# ATmega16A device description
Architecture: AVR8; Family: megaAVR
Registers are 8-bit, access not given, no defined reset value unless marked. A register's access mark holds for its fields unless they carry their own. Offsets are from the block's base; [hi:lo] are bit positions; 'fields as' and 'values as' point back to an identical list.

## EXINT — External Interrupts
Instances: EXINT 0x00
0x54 MCUCSR — MCU Control And Status Register
  [6] ISC2 — Interrupt Sense Control 2
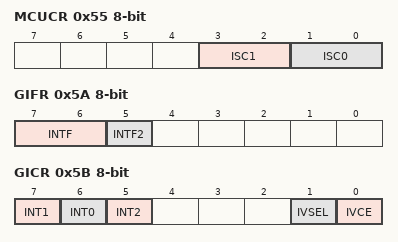
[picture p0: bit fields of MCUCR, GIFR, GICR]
0x55 MCUCR — General Interrupt Control Register
  [3:2] ISC1 — Interrupt Sense Control 1 Bits
    0=Low Level of INTX; 1=Any Logical Change of INTX; 2=Falling Edge of INTX; 3=Rising Edge of INTX
  [1:0] ISC0 — Interrupt Sense Control 0 Bits
    values as ISC1
0x5A GIFR — General Interrupt Flag Register
  [7:6] INTF — External Interrupt Flags
  [5] INTF2 — External Interrupt Flag 2
0x5B GICR — General Interrupt Control Register
  [7] INT1 — External Interrupt Request 1 Enable
  [6] INT0 — External Interrupt Request 0 Enable
  [5] INT2 — External Interrupt Request 2 Enable
  [1] IVSEL — Interrupt Vector Select
  [0] IVCE — Interrupt Vector Change Enable

## EEPROM
Instances: EEPROM 0x00
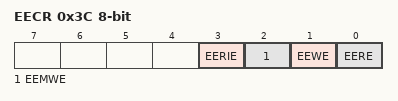
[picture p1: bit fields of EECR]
0x3C EECR — EEPROM Control Register
  [3] EERIE — EEPROM Ready Interrupt Enable
  [2] EEMWE — EEPROM Master Write Enable
  [1] EEWE — EEPROM Write Enable
  [0] EERE — EEPROM Read Enable
0x3D EEDR — EEPROM Data Register
  [7:0] EEDR — EEPROM Data bits
0x3E EEAR 16-bit — EEPROM Address Register Bytes
  [8:0] EEAR — EEPROM Address bits

## CPU — CPU Registers
Instances: CPU 0x00
Parameters: CORE_VERSION=V2E
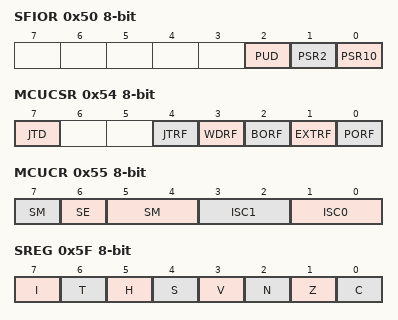
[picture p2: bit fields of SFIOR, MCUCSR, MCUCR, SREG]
0x50 SFIOR — Special function I/O register
  [2] PUD — Pull-up Disable
  [1] PSR2 — Prescaler reset
  [0] PSR10 — Prescaler reset
0x51 OSCCAL — Oscillator Calibration Value
  [7:0] OSCCAL — Oscillator Calibration
0x54 MCUCSR — MCU Control And Status Register
  [7] JTD — JTAG Interface Disable
  [4] JTRF — JTAG Reset Flag
  [3] WDRF — Watchdog Reset Flag
  [2] BORF — Brown-out Reset Flag
  [1] EXTRF — External Reset Flag
  [0] PORF — Power-on reset flag
0x55 MCUCR — MCU Control Register
  [6] SE — Sleep Enable
  [7,5:4] SM — Sleep Mode Select
    0=IDLE; 1=ADC (ADC Noise Reduction (If Available)); 2=PDOWN (Power Down); 3=PSAVE (Power Save); 10=STDBY (Standby); 11=ESTDBY (Extended Standby)
  [3:2] ISC1 — Interrupt Sense Control 1 Bits
    0=Low Level of INTX; 1=Any Logical Change in INTX; 2=Falling Edge of INTX; 3=Rising Edge of INTX
  [1:0] ISC0 — Interrupt Sense Control 0 Bits
    values as ISC1
0x5D SP 16-bit — Stack Pointer
0x5F SREG — Status Register
  [7] I — Global Interrupt Enable
  [6] T — Bit Copy Storage
  [5] H — Half Carry Flag
  [4] S — Sign Bit
  [3] V — Two's Complement Overflow Flag
  [2] N — Negative Flag
  [1] Z — Zero Flag
  [0] C — Carry Flag
Value list OSCCAL_VALUE_ADDRESSES: 0=1_0_MHz; 1=2_0_MHz; 2=4_0_MHz; 3=8_0_MHz

## TC2 (TC8_ASYNC module) — Timer/Counter, 8-bit Async
Instances: TC2 0x00
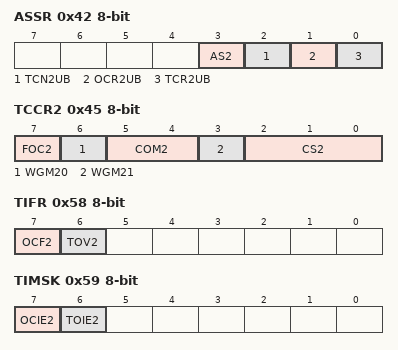
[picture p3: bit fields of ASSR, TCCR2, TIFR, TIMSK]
0x42 ASSR — Asynchronous Status Register
  [3] AS2 — Asynchronous Timer/counter2
  [2] TCN2UB — Timer/Counter2 Update Busy
  [1] OCR2UB — Output Compare Register2 Update Busy
  [0] TCR2UB — Timer/counter Control Register2 Update Busy
0x43 OCR2 — Timer/Counter2 Output Compare Register
  [7:0] OCR2 — Timer/Counter2 Output Compare bits
0x44 TCNT2 — Timer/Counter2
0x45 TCCR2 — Timer/Counter2 Control Register
  [7] FOC2 — Force Output Compare
  [6] WGM20 — Waveform Genration Mode
    0=Normal; 2=PWM, Phase Correct; 1=CTC; 3=Fast PWM
  [5:4] COM2 — Compare Output Mode bits
  [3] WGM21 — Waveform Generation Mode
  [2:0] CS2 — Clock Select bits
    0=No Clock Source (Stopped); 1=Running, No Prescaling; 2=Running, CLK/8; 3=Running, CLK/32; 4=Running, CLK/64; 5=Running, CLK/128; 6=Running, CLK/256; 7=Running, CLK/1024
0x50 SFIOR — Special Function IO Register
  [1] PSR2 — Prescaler Reset Timer/Counter2
0x58 TIFR — Timer/Counter Interrupt Flag Register
  [7] OCF2 — Output Compare Flag 2
  [6] TOV2 — Timer/Counter2 Overflow Flag
0x59 TIMSK — Timer/Counter Interrupt Mask register
  [7] OCIE2 — Timer/Counter2 Output Compare Match Interrupt Enable
  [6] TOIE2 — Timer/Counter2 Overflow Interrupt Enable
